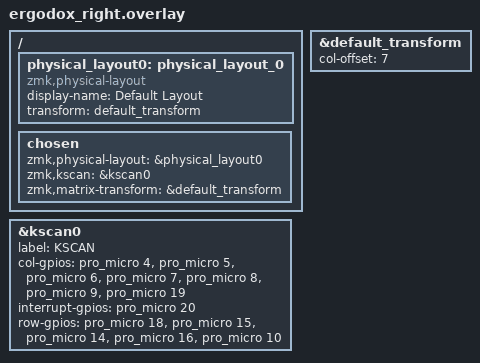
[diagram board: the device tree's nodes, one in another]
#include "ergodox.dtsi"

&default_transform {
    col-offset = <7>;
};

&kscan0 {
    label = "KSCAN";
    col-gpios
        = <&pro_micro 4 GPIO_ACTIVE_HIGH>
        , <&pro_micro 5 GPIO_ACTIVE_HIGH>
        , <&pro_micro 6 GPIO_ACTIVE_HIGH>
        , <&pro_micro 7 GPIO_ACTIVE_HIGH>
        , <&pro_micro 8 GPIO_ACTIVE_HIGH>
        , <&pro_micro 9 GPIO_ACTIVE_HIGH>
        , <&pro_micro 19 GPIO_ACTIVE_HIGH>
        ;
    interrupt-gpios 
        = <&pro_micro 20 (GPIO_ACTIVE_HIGH | GPIO_PULL_DOWN)>;
    row-gpios
        = <&pro_micro 18 (GPIO_ACTIVE_HIGH | GPIO_PULL_DOWN)>
        , <&pro_micro 15 (GPIO_ACTIVE_HIGH | GPIO_PULL_DOWN)>
        , <&pro_micro 14 (GPIO_ACTIVE_HIGH | GPIO_PULL_DOWN)>
        , <&pro_micro 16 (GPIO_ACTIVE_HIGH | GPIO_PULL_DOWN)>
        , <&pro_micro 10 (GPIO_ACTIVE_HIGH | GPIO_PULL_DOWN)>
        ;
};

/ {
    physical_layout0: physical_layout_0 {
        compatible = "zmk,physical-layout";
        display-name = "Default Layout";
        transform = <&default_transform>;
    };

    chosen {
        zmk,physical-layout = &physical_layout0;
        zmk,kscan = &kscan0;
        zmk,matrix-transform = &default_transform;
    };
};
